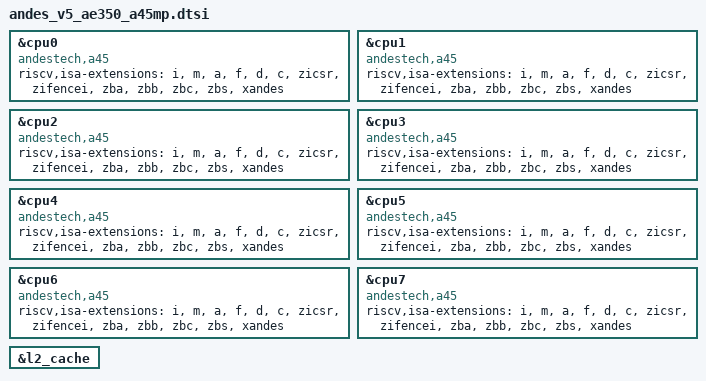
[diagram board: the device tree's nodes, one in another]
/*
 * Copyright (c) 2026 Andes Technology Corporation
 *
 * SPDX-License-Identifier: Apache-2.0
 */

#include <riscv/andes/andes_v5_ae350.dtsi>

&cpu0 {
	compatible = "andestech,a45", "andestech,andescore-v5", "riscv";
	riscv,isa-extensions = "i", "m", "a", "f", "d", "c", "zicsr", "zifencei",
			       "zba", "zbb", "zbc", "zbs", "xandes";
};

&cpu1 {
	compatible = "andestech,a45", "andestech,andescore-v5", "riscv";
	riscv,isa-extensions = "i", "m", "a", "f", "d", "c", "zicsr", "zifencei",
			       "zba", "zbb", "zbc", "zbs", "xandes";
};

&cpu2 {
	compatible = "andestech,a45", "andestech,andescore-v5", "riscv";
	riscv,isa-extensions = "i", "m", "a", "f", "d", "c", "zicsr", "zifencei",
			       "zba", "zbb", "zbc", "zbs", "xandes";
};

&cpu3 {
	compatible = "andestech,a45", "andestech,andescore-v5", "riscv";
	riscv,isa-extensions = "i", "m", "a", "f", "d", "c", "zicsr", "zifencei",
			       "zba", "zbb", "zbc", "zbs", "xandes";
};

&cpu4 {
	compatible = "andestech,a45", "andestech,andescore-v5", "riscv";
	riscv,isa-extensions = "i", "m", "a", "f", "d", "c", "zicsr", "zifencei",
			       "zba", "zbb", "zbc", "zbs", "xandes";
};

&cpu5 {
	compatible = "andestech,a45", "andestech,andescore-v5", "riscv";
	riscv,isa-extensions = "i", "m", "a", "f", "d", "c", "zicsr", "zifencei",
			       "zba", "zbb", "zbc", "zbs", "xandes";
};

&cpu6 {
	compatible = "andestech,a45", "andestech,andescore-v5", "riscv";
	riscv,isa-extensions = "i", "m", "a", "f", "d", "c", "zicsr", "zifencei",
			       "zba", "zbb", "zbc", "zbs", "xandes";
};

&cpu7 {
	compatible = "andestech,a45", "andestech,andescore-v5", "riscv";
	riscv,isa-extensions = "i", "m", "a", "f", "d", "c", "zicsr", "zifencei",
			       "zba", "zbb", "zbc", "zbs", "xandes";
};

&l2_cache {
	status = "okay";
};
